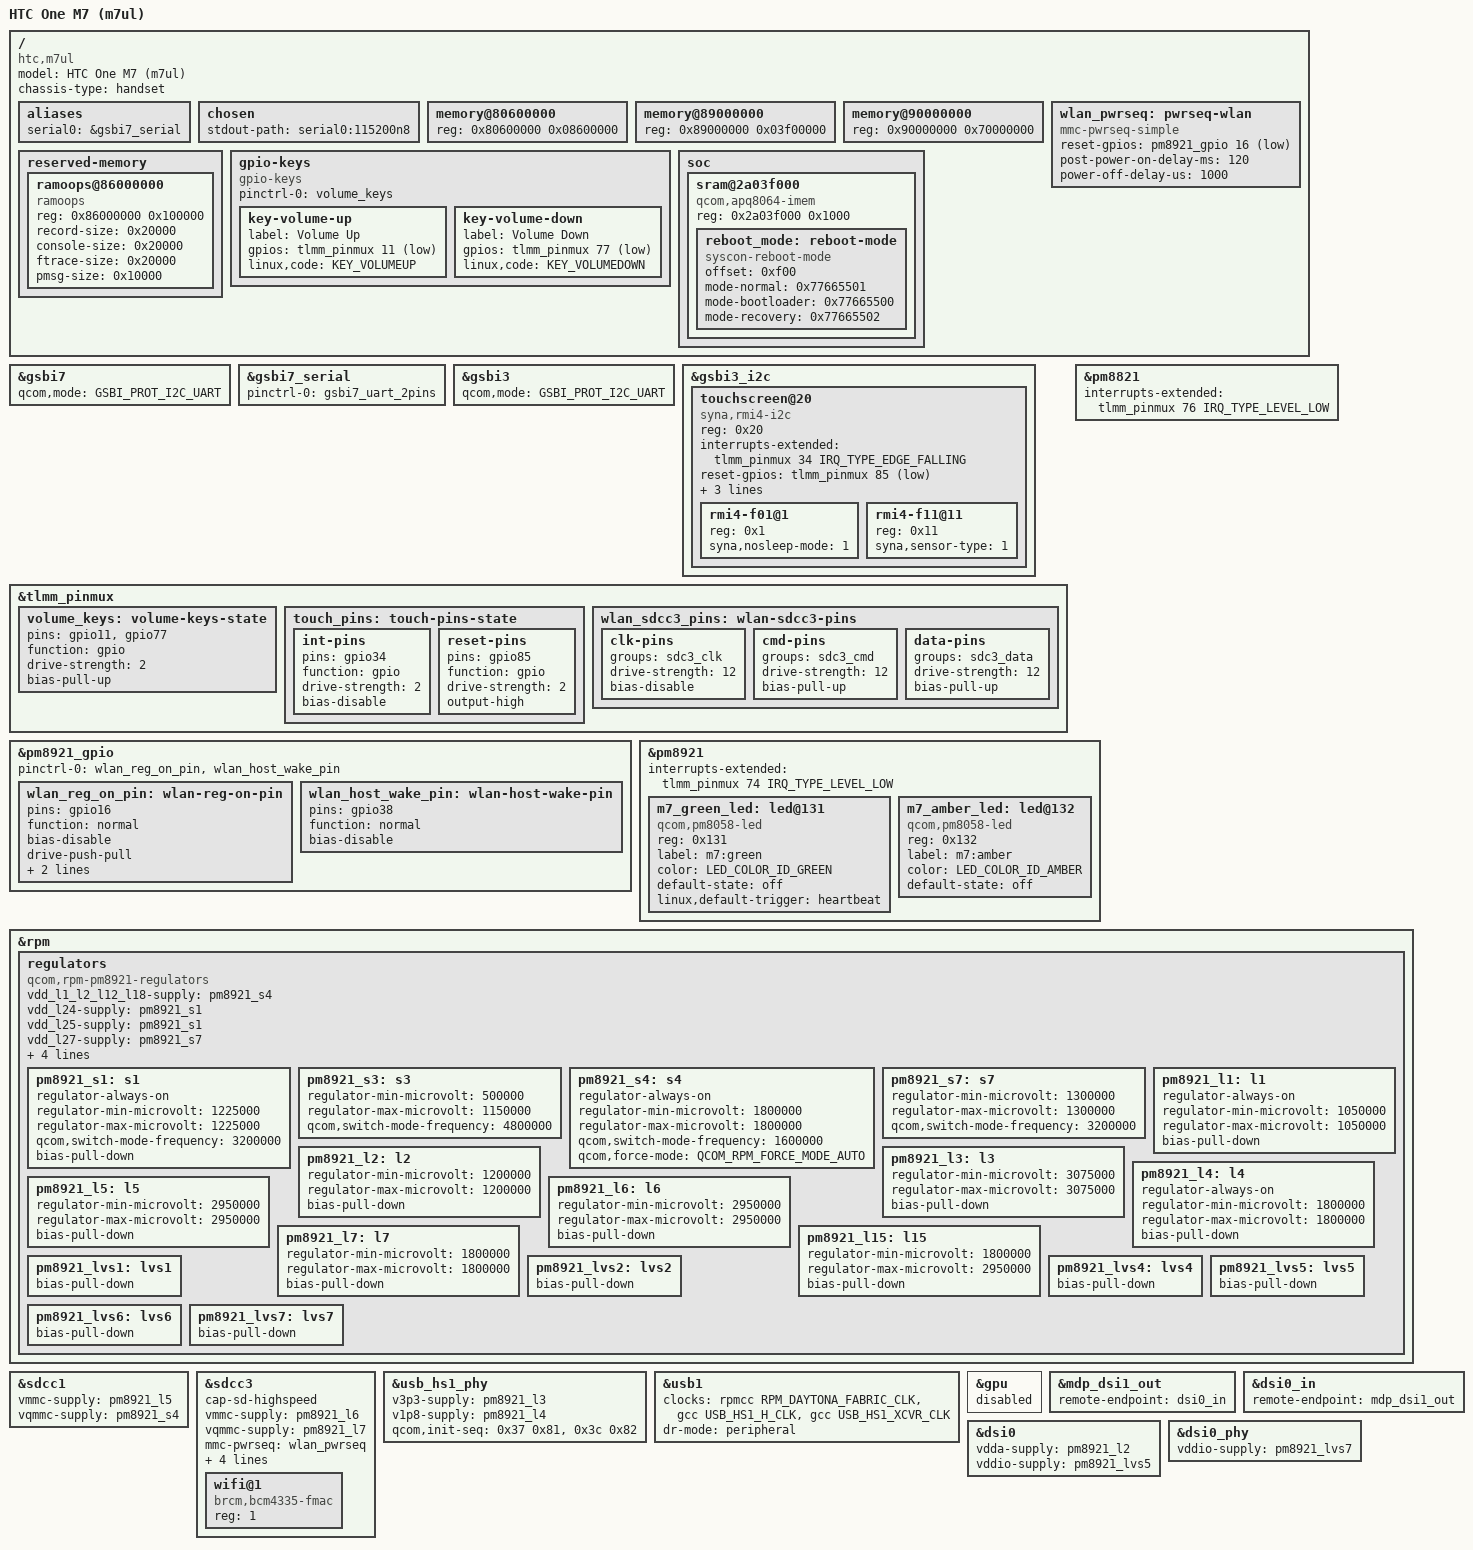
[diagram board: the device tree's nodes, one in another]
// SPDX-License-Identifier: GPL-2.0-only
#include <dt-bindings/gpio/gpio.h>
#include <dt-bindings/input/input.h>
#include <dt-bindings/leds/common.h>
#include <dt-bindings/mfd/qcom-rpm.h>
#include <dt-bindings/pinctrl/qcom,pmic-gpio.h>

#include "qcom-apq8064-v2.0.dtsi"
#include "pm8821.dtsi"
#include "pm8921.dtsi"

/ {
	model = "HTC One M7 (m7ul)";
	compatible = "htc,m7ul", "htc,m7", "qcom,apq8064";
	chassis-type = "handset";

	aliases {
		serial0 = &gsbi7_serial;
	};

	chosen {
		stdout-path = "serial0:115200n8";
	};

	memory@80600000 {
		device_type = "memory";
		reg = <0x80600000 0x08600000>;
	};

	memory@89000000 {
		device_type = "memory";
		reg = <0x89000000 0x03f00000>;
	};

	memory@90000000 {
		device_type = "memory";
		reg = <0x90000000 0x70000000>;
	};

	wlan_pwrseq: pwrseq-wlan {
		compatible = "mmc-pwrseq-simple";
		reset-gpios = <&pm8921_gpio 16 GPIO_ACTIVE_LOW>;
		post-power-on-delay-ms = <120>;
		power-off-delay-us = <1000>;
	};

	reserved-memory {
		#address-cells = <1>;
		#size-cells = <1>;
		ranges;

		ramoops@86000000 {
			compatible = "ramoops";
			reg = <0x86000000 0x100000>;
			record-size = <0x20000>;
			console-size = <0x20000>;
			ftrace-size = <0x20000>;
			pmsg-size = <0x10000>;
		};
	};

	gpio-keys {
		compatible = "gpio-keys";
		pinctrl-names = "default";
		pinctrl-0 = <&volume_keys>;

		key-volume-up {
			label = "Volume Up";
			gpios = <&tlmm_pinmux 11 GPIO_ACTIVE_LOW>;
			linux,code = <KEY_VOLUMEUP>;
		};

		key-volume-down {
			label = "Volume Down";
			gpios = <&tlmm_pinmux 77 GPIO_ACTIVE_LOW>;
			linux,code = <KEY_VOLUMEDOWN>;
		};
	};

	soc {
		sram@2a03f000 {
			compatible = "qcom,apq8064-imem", "syscon", "simple-mfd";
			reg = <0x2a03f000 0x1000>;

			reboot_mode: reboot-mode {
				compatible = "syscon-reboot-mode";
				offset = <0xf00>;

				mode-normal = <0x77665501>;
				mode-bootloader = <0x77665500>;
				mode-recovery = <0x77665502>;
			};
		};
	};
};

&gsbi7 {
	qcom,mode = <GSBI_PROT_I2C_UART>;
	status = "okay";
};

&gsbi7_serial {
	pinctrl-names = "default";
	pinctrl-0 = <&gsbi7_uart_2pins>;
	status = "okay";
};

&gsbi3 {
	qcom,mode = <GSBI_PROT_I2C_UART>;
	status = "okay";
};

&gsbi3_i2c {
	status = "okay";

	touchscreen@20 {
		compatible = "syna,rmi4-i2c";
		reg = <0x20>;

		interrupts-extended = <&tlmm_pinmux 34 IRQ_TYPE_EDGE_FALLING>;
		reset-gpios = <&tlmm_pinmux 85 GPIO_ACTIVE_LOW>;
		pinctrl-names = "default";
		pinctrl-0 = <&touch_pins>;
		vdd-supply = <&pm8921_l15>;

		syna,startup-delay-ms = <100>;

		#address-cells = <1>;
		#size-cells = <0>;

		rmi4-f01@1 {
			reg = <0x1>;
			syna,nosleep-mode = <1>;
		};

		rmi4-f11@11 {
			reg = <0x11>;
			syna,sensor-type = <1>;
		};
	};
};

&tlmm_pinmux {
	volume_keys: volume-keys-state {
		pins = "gpio11", "gpio77";
		function = "gpio";
		drive-strength = <2>;
		bias-pull-up;
	};

	touch_pins: touch-pins-state {
		int-pins {
			pins = "gpio34";
			function = "gpio";
			drive-strength = <2>;
			bias-disable;
		};

		reset-pins {
			pins = "gpio85";
			function = "gpio";
			drive-strength = <2>;
			output-high;
		};
	};

	wlan_sdcc3_pins: wlan-sdcc3-pins {
		clk-pins {
			groups = "sdc3_clk";
			drive-strength = <12>;
			bias-disable;
		};

		cmd-pins {
			groups = "sdc3_cmd";
			drive-strength = <12>;
			bias-pull-up;
		};

		data-pins {
			groups = "sdc3_data";
			drive-strength = <12>;
			bias-pull-up;
		};
	};
};

&pm8821 {
	interrupts-extended = <&tlmm_pinmux 76 IRQ_TYPE_LEVEL_LOW>;
};

&pm8921_gpio {
	pinctrl-names = "default";
	pinctrl-0 = <&wlan_reg_on_pin>, <&wlan_host_wake_pin>;

	wlan_reg_on_pin: wlan-reg-on-pin {
		pins = "gpio16";
		function = "normal";
		bias-disable;
		drive-push-pull;
		qcom,drive-strength = <PMIC_GPIO_STRENGTH_LOW>;
		power-source = <PM8921_GPIO_S4>;
	};

	wlan_host_wake_pin: wlan-host-wake-pin {
		pins = "gpio38";
		function = "normal";
		bias-disable;
	};
};

&pm8921 {
	interrupts-extended = <&tlmm_pinmux 74 IRQ_TYPE_LEVEL_LOW>;

	m7_green_led: led@131 {
		compatible = "qcom,pm8058-led";
		reg = <0x131>;
		label = "m7:green";
		color = <LED_COLOR_ID_GREEN>;
		default-state = "off";
		linux,default-trigger = "heartbeat";
	};

	m7_amber_led: led@132 {
		compatible = "qcom,pm8058-led";
		reg = <0x132>;
		label = "m7:amber";
		color = <LED_COLOR_ID_AMBER>;
		default-state = "off";
	};
};

&rpm {
	regulators {
		compatible = "qcom,rpm-pm8921-regulators";

		vdd_l1_l2_l12_l18-supply = <&pm8921_s4>;
		vdd_l24-supply = <&pm8921_s1>;
		vdd_l25-supply = <&pm8921_s1>;
		vdd_l27-supply = <&pm8921_s7>;
		vdd_ncp-supply = <&pm8921_l6>;
		vin_lvs1_3_6-supply = <&pm8921_s4>;
		vin_lvs2-supply = <&pm8921_s1>;
		vin_lvs4_5_7-supply = <&pm8921_s4>;

		pm8921_s1: s1 {
			regulator-always-on;
			regulator-min-microvolt = <1225000>;
			regulator-max-microvolt = <1225000>;
			qcom,switch-mode-frequency = <3200000>;
			bias-pull-down;
		};

		pm8921_s3: s3 {
			regulator-min-microvolt = <500000>;
			regulator-max-microvolt = <1150000>;
			qcom,switch-mode-frequency = <4800000>;
		};

		pm8921_s4: s4 {
			regulator-always-on;
			regulator-min-microvolt = <1800000>;
			regulator-max-microvolt = <1800000>;
			qcom,switch-mode-frequency = <1600000>;
			qcom,force-mode = <QCOM_RPM_FORCE_MODE_AUTO>;
		};

		pm8921_s7: s7 {
			regulator-min-microvolt = <1300000>;
			regulator-max-microvolt = <1300000>;
			qcom,switch-mode-frequency = <3200000>;
		};

		pm8921_l1: l1 {
			regulator-always-on;
			regulator-min-microvolt = <1050000>;
			regulator-max-microvolt = <1050000>;
			bias-pull-down;
		};

		pm8921_l2: l2 {
			regulator-min-microvolt = <1200000>;
			regulator-max-microvolt = <1200000>;
			bias-pull-down;
		};

		pm8921_l3: l3 {
			regulator-min-microvolt = <3075000>;
			regulator-max-microvolt = <3075000>;
			bias-pull-down;
		};

		pm8921_l4: l4 {
			regulator-always-on;
			regulator-min-microvolt = <1800000>;
			regulator-max-microvolt = <1800000>;
			bias-pull-down;
		};

		pm8921_l5: l5 {
			regulator-min-microvolt = <2950000>;
			regulator-max-microvolt = <2950000>;
			bias-pull-down;
		};

		pm8921_l6: l6 {
			regulator-min-microvolt = <2950000>;
			regulator-max-microvolt = <2950000>;
			bias-pull-down;
		};

		pm8921_l7: l7 {
			regulator-min-microvolt = <1800000>;
			regulator-max-microvolt = <1800000>;
			bias-pull-down;
		};

		pm8921_l15: l15 {
			regulator-min-microvolt = <1800000>;
			regulator-max-microvolt = <2950000>;
			bias-pull-down;
		};

		pm8921_lvs1: lvs1 {
			bias-pull-down;
		};

		pm8921_lvs2: lvs2 {
			bias-pull-down;
		};

		pm8921_lvs4: lvs4 {
			bias-pull-down;
		};

		pm8921_lvs5: lvs5 {
			bias-pull-down;
		};

		pm8921_lvs6: lvs6 {
			bias-pull-down;
		};

		pm8921_lvs7: lvs7 {
			bias-pull-down;
		};
	};
};

&sdcc1 {
	vmmc-supply = <&pm8921_l5>;
	vqmmc-supply = <&pm8921_s4>;
	status = "okay";
};

&sdcc3 {
	cap-sd-highspeed;

	#address-cells = <1>;
	#size-cells = <0>;
	vmmc-supply = <&pm8921_l6>;
	vqmmc-supply = <&pm8921_l7>;
	mmc-pwrseq = <&wlan_pwrseq>;
	pinctrl-names = "default";
	pinctrl-0 = <&wlan_sdcc3_pins>;
	bus-width = <1>;
	max-frequency = <1000000>;
	non-removable;
	status = "okay";

	wifi@1 {
		compatible = "brcm,bcm4335-fmac", "brcm,bcm4329-fmac";
		reg = <1>;
		/* OOB is not delivered on this board; poll SDIO interrupts in MMC. */
	};
};

&usb_hs1_phy {
	v3p3-supply = <&pm8921_l3>;
	v1p8-supply = <&pm8921_l4>;
	qcom,init-seq = /bits/ 8 <0x37 0x81>, <0x3c 0x82>;
};

&usb1 {
	clocks = <&rpmcc RPM_DAYTONA_FABRIC_CLK>, <&gcc USB_HS1_H_CLK>,
		 <&gcc USB_HS1_XCVR_CLK>;
	clock-names = "iface", "core", "fs";
	dr-mode = "peripheral";
	status = "okay";
};

/*
 * The adreno-320.2 GPU node is enabled in the SoC dtsi but has ten gfx3d
 * stream IDs and no vdd regulator. When DRM_MSM is on, the MDP4 display
 * controller binds the GPU, that bind fails with -19, and the cleanup oopses
 * in msm_iommu_identity_attach, which the watchdog turns into a reset loop.
 * The display path does not need the GPU, so keep it off until it is brought
 * up properly with the right stream IDs and regulators.
 */
&gpu {
	status = "disabled";
};

/*
 * The M7 downstream panel path uses L2 for DSI VDDA, LVS5 for DSI VDDIO and
 * LVS7 for the PHY VDDIO. It has no separate DSI AVDD consumer; L11 powers
 * MHL instead. Leave AVDD unconnected rather than copying the Nexus 7 rail.
 */
&mdp_dsi1_out {
	remote-endpoint = <&dsi0_in>;
};

&dsi0_in {
	remote-endpoint = <&mdp_dsi1_out>;
};

&dsi0 {
	vdda-supply = <&pm8921_l2>;
	vddio-supply = <&pm8921_lvs5>;
	status = "okay";
};

&dsi0_phy {
	vddio-supply = <&pm8921_lvs7>;
	status = "okay";
};
